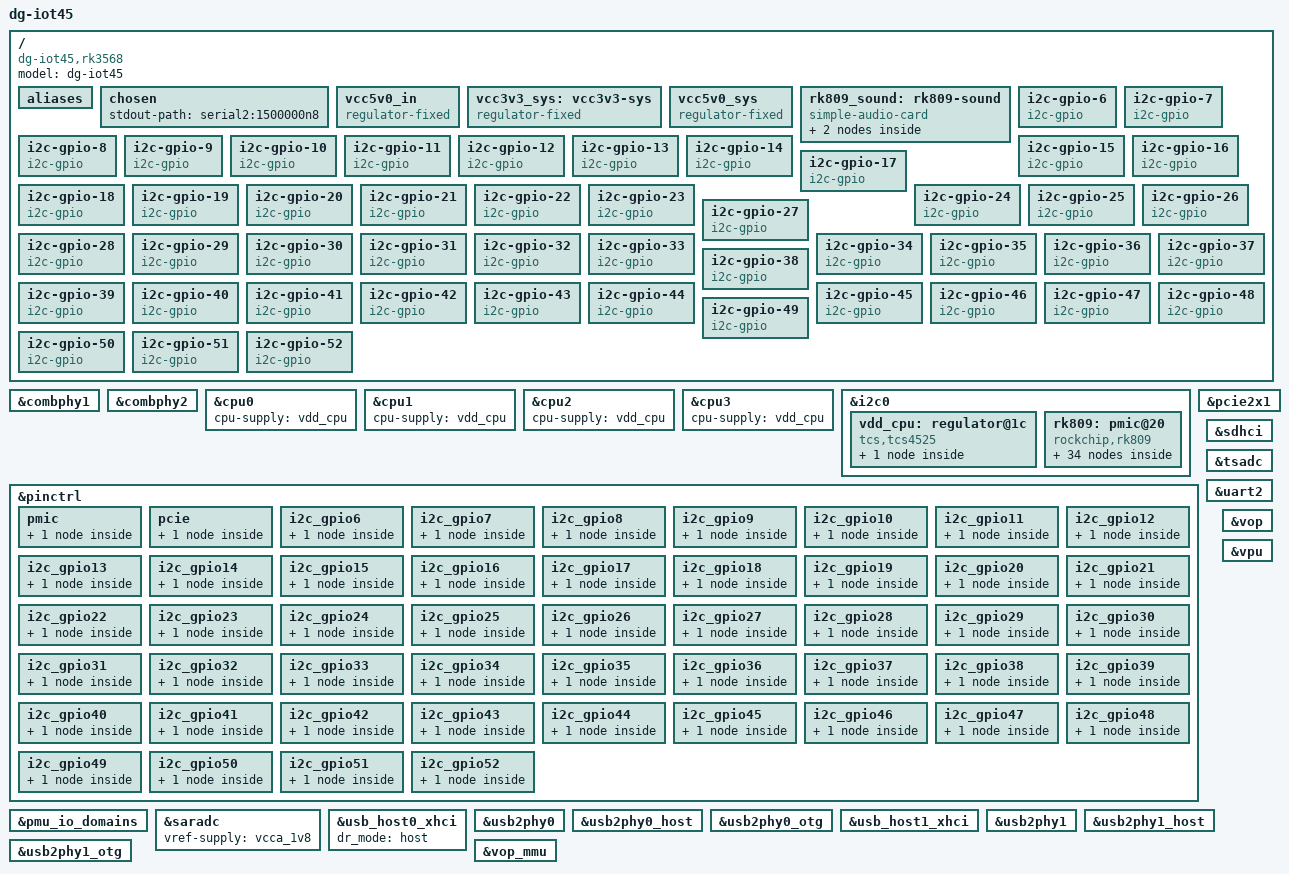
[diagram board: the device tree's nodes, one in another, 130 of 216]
// SPDX-License-Identifier: (GPL-2.0+ OR MIT)
/*
 * Copyright (c) 2020 Rockchip Electronics Co., Ltd.
 *
 */

/dts-v1/;

#include <dt-bindings/gpio/gpio.h>
#include <dt-bindings/input/input.h>
#include <dt-bindings/pinctrl/rockchip.h>
#include <dt-bindings/soc/rockchip,vop2.h>
#include "rk3568.dtsi"

/ {
	model = "dg-iot45";
	compatible = "dg-iot45,rk3568", "rockchip,rk3568";

	aliases {
		ethernet0 = &gmac1;
		mmc0 = &sdmmc0;
		mmc1 = &sdhci;
		mmc2 = &sdmmc1;
	};

	chosen: chosen {
		stdout-path = "serial2:1500000n8";
	};

	vcc5v0_in: vcc5v0_in {
		compatible = "regulator-fixed";
		regulator-name = "vcc5v0_in";
		regulator-always-on;
		regulator-boot-on;
		regulator-min-microvolt = <5000000>;
		regulator-max-microvolt = <5000000>;
	};

	vcc3v3_sys: vcc3v3-sys {
		compatible = "regulator-fixed";
		regulator-name = "vcc3v3_sys";
		regulator-always-on;
		regulator-boot-on;
		regulator-min-microvolt = <3300000>;
		regulator-max-microvolt = <3300000>;
		vin-supply = <&vcc5v0_sys>;
	};

	vcc5v0_sys: vcc5v0_sys {
		compatible = "regulator-fixed";
		regulator-name = "vcc5v0_sys";
		regulator-always-on;
		regulator-boot-on;
		regulator-min-microvolt = <5000000>;
		regulator-max-microvolt = <5000000>;
		vin-supply = <&vcc5v0_in>;
	};

	rk809_sound: rk809-sound {
		status = "okay";
		compatible = "simple-audio-card";
		simple-audio-card,format = "i2s";
		simple-audio-card,name = "rockchip,rk809-codec";
		simple-audio-card,mclk-fs = <256>;

		simple-audio-card,cpu {
			sound-dai = <&i2s1_8ch>;
		};
		simple-audio-card,codec {
			sound-dai = <&rk809_codec>;
		};
	};

	i2c-gpio-6 {
               compatible = "i2c-gpio";
               gpios = <&gpio0 RK_PC1 GPIO_ACTIVE_HIGH>, /* sda */
                               <&gpio0 RK_PC0 GPIO_ACTIVE_HIGH>; /* scl */
               i2c-gpio,sda-open-drain;
               i2c-gpio,scl-open-drain;
               i2c-gpio,delay-us = <2>;        /* ~100 kHz */
               #address-cells = <1>;
               #size-cells = <0>;
               pinctrl-names = "default";
               pinctrl-0 = <&pinctrl_i2c_gpio6>;
               status = "okay";
       };

       i2c-gpio-7 {
               compatible = "i2c-gpio";
               gpios = <&gpio0 RK_PC3 GPIO_ACTIVE_HIGH>, /* sda */
                               <&gpio0 RK_PC2 GPIO_ACTIVE_HIGH>; /* scl */
               i2c-gpio,sda-open-drain;
               i2c-gpio,scl-open-drain;
               i2c-gpio,delay-us = <2>;        /* ~100 kHz */
               #address-cells = <1>;
               #size-cells = <0>;
               pinctrl-names = "default";
               pinctrl-0 = <&pinctrl_i2c_gpio7>;
               status = "okay";
       };

       i2c-gpio-8 {
               compatible = "i2c-gpio";
               gpios = <&gpio0 RK_PC5 GPIO_ACTIVE_HIGH>, /* sda */
                               <&gpio0 RK_PC4 GPIO_ACTIVE_HIGH>; /* scl */
               i2c-gpio,sda-open-drain;
               i2c-gpio,scl-open-drain;
               i2c-gpio,delay-us = <2>;        /* ~100 kHz */
               #address-cells = <1>;
               #size-cells = <0>;
               pinctrl-names = "default";
               pinctrl-0 = <&pinctrl_i2c_gpio8>;
               status = "okay";
       };

       i2c-gpio-9 {
               compatible = "i2c-gpio";
               gpios = <&gpio0 RK_PC7 GPIO_ACTIVE_HIGH>, /* sda */
                               <&gpio0 RK_PC6 GPIO_ACTIVE_HIGH>; /* scl */
               i2c-gpio,sda-open-drain;
               i2c-gpio,scl-open-drain;
               i2c-gpio,delay-us = <2>;        /* ~100 kHz */
               #address-cells = <1>;
               #size-cells = <0>;
               pinctrl-names = "default";
               pinctrl-0 = <&pinctrl_i2c_gpio9>;
               status = "okay";
       };

       i2c-gpio-10 {
               compatible = "i2c-gpio";
               gpios = <&gpio4 RK_PC3 GPIO_ACTIVE_HIGH>, /* sda */
                               <&gpio4 RK_PC2 GPIO_ACTIVE_HIGH>; /* scl */
               i2c-gpio,sda-open-drain;
               i2c-gpio,scl-open-drain;
               i2c-gpio,delay-us = <2>;        /* ~100 kHz */
               #address-cells = <1>;
               #size-cells = <0>;
               pinctrl-names = "default";
               pinctrl-0 = <&pinctrl_i2c_gpio10>;
               status = "okay";
       };

       i2c-gpio-11 {
               compatible = "i2c-gpio";
               gpios = <&gpio4 RK_PC5 GPIO_ACTIVE_HIGH>, /* sda */
                               <&gpio4 RK_PC4 GPIO_ACTIVE_HIGH>; /* scl */
               i2c-gpio,sda-open-drain;
               i2c-gpio,scl-open-drain;
               i2c-gpio,delay-us = <2>;        /* ~100 kHz */
               #address-cells = <1>;
               #size-cells = <0>;
               pinctrl-names = "default";
               pinctrl-0 = <&pinctrl_i2c_gpio11>;
               status = "okay";
       };

       i2c-gpio-12 {
               compatible = "i2c-gpio";
               gpios = <&gpio0 RK_PB4 GPIO_ACTIVE_HIGH>, /* sda */
                               <&gpio0 RK_PB3 GPIO_ACTIVE_HIGH>; /* scl */
               i2c-gpio,sda-open-drain;
               i2c-gpio,scl-open-drain;
               i2c-gpio,delay-us = <2>;        /* ~100 kHz */
               #address-cells = <1>;
               #size-cells = <0>;
               pinctrl-names = "default";
               pinctrl-0 = <&pinctrl_i2c_gpio12>;
               status = "okay";
       };

       i2c-gpio-13 {
               compatible = "i2c-gpio";
               gpios = <&gpio0 RK_PB6 GPIO_ACTIVE_HIGH>, /* sda */
                               <&gpio0 RK_PB5 GPIO_ACTIVE_HIGH>; /* scl */
               i2c-gpio,sda-open-drain;
               i2c-gpio,scl-open-drain;
               i2c-gpio,delay-us = <2>;        /* ~100 kHz */
               #address-cells = <1>;
               #size-cells = <0>;
               pinctrl-names = "default";
               pinctrl-0 = <&pinctrl_i2c_gpio13>;
               status = "okay";
       };

       i2c-gpio-14 {
               compatible = "i2c-gpio";
               gpios = <&gpio1 RK_PA1 GPIO_ACTIVE_HIGH>, /* sda */
                               <&gpio1 RK_PA0 GPIO_ACTIVE_HIGH>; /* scl */
               i2c-gpio,sda-open-drain;
               i2c-gpio,scl-open-drain;
               i2c-gpio,delay-us = <2>;        /* ~100 kHz */
               #address-cells = <1>;
               #size-cells = <0>;
               pinctrl-names = "default";
               pinctrl-0 = <&pinctrl_i2c_gpio14>;
               status = "okay";
       };

       i2c-gpio-15 {
               compatible = "i2c-gpio";
               gpios = <&gpio2 RK_PA4 GPIO_ACTIVE_HIGH>, /* sda */
                               <&gpio2 RK_PA3 GPIO_ACTIVE_HIGH>; /* scl */
               i2c-gpio,sda-open-drain;
               i2c-gpio,scl-open-drain;
               i2c-gpio,delay-us = <2>;        /* ~100 kHz */
               #address-cells = <1>;
               #size-cells = <0>;
               pinctrl-names = "default";
               pinctrl-0 = <&pinctrl_i2c_gpio15>;
               status = "okay";
       };

       i2c-gpio-16 {
               compatible = "i2c-gpio";
               gpios = <&gpio2 RK_PA6 GPIO_ACTIVE_HIGH>, /* sda */
                               <&gpio2 RK_PA5 GPIO_ACTIVE_HIGH>; /* scl */
               i2c-gpio,sda-open-drain;
               i2c-gpio,scl-open-drain;
               i2c-gpio,delay-us = <2>;        /* ~100 kHz */
               #address-cells = <1>;
               #size-cells = <0>;
               pinctrl-names = "default";
               pinctrl-0 = <&pinctrl_i2c_gpio16>;
               status = "okay";
       };

       i2c-gpio-17 {
               compatible = "i2c-gpio";
               gpios = <&gpio2 RK_PB0 GPIO_ACTIVE_HIGH>, /* sda */
                               <&gpio2 RK_PA7 GPIO_ACTIVE_HIGH>; /* scl */
               i2c-gpio,sda-open-drain;
               i2c-gpio,scl-open-drain;
               i2c-gpio,delay-us = <2>;        /* ~100 kHz */
               #address-cells = <1>;
               #size-cells = <0>;
               pinctrl-names = "default";
               pinctrl-0 = <&pinctrl_i2c_gpio17>;
               status = "okay";
       };

       i2c-gpio-18 {
               compatible = "i2c-gpio";
               gpios = <&gpio2 RK_PB2 GPIO_ACTIVE_HIGH>, /* sda */
                               <&gpio2 RK_PB1 GPIO_ACTIVE_HIGH>; /* scl */
               i2c-gpio,sda-open-drain;
               i2c-gpio,scl-open-drain;
               i2c-gpio,delay-us = <2>;        /* ~100 kHz */
               #address-cells = <1>;
               #size-cells = <0>;
               pinctrl-names = "default";
               pinctrl-0 = <&pinctrl_i2c_gpio18>;
               status = "okay";
       };

       i2c-gpio-19 {
               compatible = "i2c-gpio";
               gpios = <&gpio2 RK_PB4 GPIO_ACTIVE_HIGH>, /* sda */
                               <&gpio2 RK_PB3 GPIO_ACTIVE_HIGH>; /* scl */
               i2c-gpio,sda-open-drain;
               i2c-gpio,scl-open-drain;
               i2c-gpio,delay-us = <2>;        /* ~100 kHz */
               #address-cells = <1>;
               #size-cells = <0>;
               pinctrl-names = "default";
               pinctrl-0 = <&pinctrl_i2c_gpio19>;
               status = "okay";
       };

       i2c-gpio-20 {
               compatible = "i2c-gpio";
               gpios = <&gpio2 RK_PB6 GPIO_ACTIVE_HIGH>, /* sda */
                               <&gpio2 RK_PB5 GPIO_ACTIVE_HIGH>; /* scl */
               i2c-gpio,sda-open-drain;
               i2c-gpio,scl-open-drain;
               i2c-gpio,delay-us = <2>;        /* ~100 kHz */
               #address-cells = <1>;
               #size-cells = <0>;
               pinctrl-names = "default";
               pinctrl-0 = <&pinctrl_i2c_gpio20>;
               status = "okay";
       };

       i2c-gpio-21 {
               compatible = "i2c-gpio";
               gpios = <&gpio2 RK_PC0 GPIO_ACTIVE_HIGH>, /* sda */
                               <&gpio2 RK_PB7 GPIO_ACTIVE_HIGH>; /* scl */
               i2c-gpio,sda-open-drain;
               i2c-gpio,scl-open-drain;
               i2c-gpio,delay-us = <2>;        /* ~100 kHz */
               #address-cells = <1>;
               #size-cells = <0>;
               pinctrl-names = "default";
               pinctrl-0 = <&pinctrl_i2c_gpio21>;
               status = "okay";
       };

       i2c-gpio-22 {
               compatible = "i2c-gpio";
               gpios = <&gpio2 RK_PC2 GPIO_ACTIVE_HIGH>, /* sda */
                               <&gpio2 RK_PC1 GPIO_ACTIVE_HIGH>; /* scl */
               i2c-gpio,sda-open-drain;
               i2c-gpio,scl-open-drain;
               i2c-gpio,delay-us = <2>;        /* ~100 kHz */
               #address-cells = <1>;
               #size-cells = <0>;
               pinctrl-names = "default";
               pinctrl-0 = <&pinctrl_i2c_gpio22>;
               status = "okay";
       };

       i2c-gpio-23 {
               compatible = "i2c-gpio";
               gpios = <&gpio2 RK_PC4 GPIO_ACTIVE_HIGH>, /* sda */
                               <&gpio2 RK_PC3 GPIO_ACTIVE_HIGH>; /* scl */
               i2c-gpio,sda-open-drain;
               i2c-gpio,scl-open-drain;
               i2c-gpio,delay-us = <2>;        /* ~100 kHz */
               #address-cells = <1>;
               #size-cells = <0>;
               pinctrl-names = "default";
               pinctrl-0 = <&pinctrl_i2c_gpio23>;
               status = "okay";
       };

       i2c-gpio-24 {
               compatible = "i2c-gpio";
               gpios = <&gpio2 RK_PC6 GPIO_ACTIVE_HIGH>, /* sda */
                               <&gpio2 RK_PC5 GPIO_ACTIVE_HIGH>; /* scl */
               i2c-gpio,sda-open-drain;
               i2c-gpio,scl-open-drain;
               i2c-gpio,delay-us = <2>;        /* ~100 kHz */
               #address-cells = <1>;
               #size-cells = <0>;
               pinctrl-names = "default";
               pinctrl-0 = <&pinctrl_i2c_gpio24>;
               status = "okay";
       };

       i2c-gpio-25 {
               compatible = "i2c-gpio";
               gpios = <&gpio0 RK_PA4 GPIO_ACTIVE_HIGH>, /* sda */
                               <&gpio0 RK_PA5 GPIO_ACTIVE_HIGH>; /* scl */
               i2c-gpio,sda-open-drain;
               i2c-gpio,scl-open-drain;
               i2c-gpio,delay-us = <2>;        /* ~100 kHz */
               #address-cells = <1>;
               #size-cells = <0>;
               pinctrl-names = "default";
               pinctrl-0 = <&pinctrl_i2c_gpio25>;
               status = "okay";
       };

       i2c-gpio-26 {
               compatible = "i2c-gpio";
               gpios = <&gpio2 RK_PA1 GPIO_ACTIVE_HIGH>, /* sda */
                               <&gpio2 RK_PA2 GPIO_ACTIVE_HIGH>; /* scl */
               i2c-gpio,sda-open-drain;
               i2c-gpio,scl-open-drain;
               i2c-gpio,delay-us = <2>;        /* ~100 kHz */
               #address-cells = <1>;
               #size-cells = <0>;
               pinctrl-names = "default";
               pinctrl-0 = <&pinctrl_i2c_gpio26>;
               status = "okay";
       };

       i2c-gpio-27 {
               compatible = "i2c-gpio";
               gpios = <&gpio1 RK_PD7 GPIO_ACTIVE_HIGH>, /* sda */
                               <&gpio2 RK_PA0 GPIO_ACTIVE_HIGH>; /* scl */
               i2c-gpio,sda-open-drain;
               i2c-gpio,scl-open-drain;
               i2c-gpio,delay-us = <2>;        /* ~100 kHz */
               #address-cells = <1>;
               #size-cells = <0>;
               pinctrl-names = "default";
               pinctrl-0 = <&pinctrl_i2c_gpio27>;
               status = "okay";
       };

       i2c-gpio-28 {
               compatible = "i2c-gpio";
               gpios = <&gpio1 RK_PD5 GPIO_ACTIVE_HIGH>, /* sda */
                               <&gpio1 RK_PD6 GPIO_ACTIVE_HIGH>; /* scl */
               i2c-gpio,sda-open-drain;
               i2c-gpio,scl-open-drain;
               i2c-gpio,delay-us = <2>;        /* ~100 kHz */
               #address-cells = <1>;
               #size-cells = <0>;
               pinctrl-names = "default";
               pinctrl-0 = <&pinctrl_i2c_gpio28>;
               status = "okay";
       };

       i2c-gpio-29 {
               compatible = "i2c-gpio";
               gpios = <&gpio4 RK_PC0 GPIO_ACTIVE_HIGH>, /* sda */
                               <&gpio4 RK_PC1 GPIO_ACTIVE_HIGH>; /* scl */
               i2c-gpio,sda-open-drain;
               i2c-gpio,scl-open-drain;
               i2c-gpio,delay-us = <2>;        /* ~100 kHz */
               #address-cells = <1>;
               #size-cells = <0>;
               pinctrl-names = "default";
               pinctrl-0 = <&pinctrl_i2c_gpio29>;
               status = "okay";
       };

       i2c-gpio-30 {
               compatible = "i2c-gpio";
               gpios = <&gpio4 RK_PB6 GPIO_ACTIVE_HIGH>, /* sda */
                               <&gpio4 RK_PB7 GPIO_ACTIVE_HIGH>; /* scl */
               i2c-gpio,sda-open-drain;
               i2c-gpio,scl-open-drain;
               i2c-gpio,delay-us = <2>;        /* ~100 kHz */
               #address-cells = <1>;
               #size-cells = <0>;
               pinctrl-names = "default";
               pinctrl-0 = <&pinctrl_i2c_gpio30>;
               status = "okay";
       };

       i2c-gpio-31 {
               compatible = "i2c-gpio";
               gpios = <&gpio4 RK_PB4 GPIO_ACTIVE_HIGH>, /* sda */
                               <&gpio4 RK_PB5 GPIO_ACTIVE_HIGH>; /* scl */
               i2c-gpio,sda-open-drain;
               i2c-gpio,scl-open-drain;
               i2c-gpio,delay-us = <2>;        /* ~100 kHz */
               #address-cells = <1>;
               #size-cells = <0>;
               pinctrl-names = "default";
               pinctrl-0 = <&pinctrl_i2c_gpio31>;
               status = "okay";
       };

       i2c-gpio-32 {
               compatible = "i2c-gpio";
               gpios = <&gpio4 RK_PB2 GPIO_ACTIVE_HIGH>, /* sda */
                               <&gpio4 RK_PB3 GPIO_ACTIVE_HIGH>; /* scl */
               i2c-gpio,sda-open-drain;
               i2c-gpio,scl-open-drain;
               i2c-gpio,delay-us = <2>;        /* ~100 kHz */
               #address-cells = <1>;
               #size-cells = <0>;
               pinctrl-names = "default";
               pinctrl-0 = <&pinctrl_i2c_gpio32>;
               status = "okay";
       };

       i2c-gpio-33 {
               compatible = "i2c-gpio";
               gpios = <&gpio4 RK_PB0 GPIO_ACTIVE_HIGH>, /* sda */
                               <&gpio4 RK_PB1 GPIO_ACTIVE_HIGH>; /* scl */
               i2c-gpio,sda-open-drain;
               i2c-gpio,scl-open-drain;
               i2c-gpio,delay-us = <2>;        /* ~100 kHz */
               #address-cells = <1>;
               #size-cells = <0>;
               pinctrl-names = "default";
               pinctrl-0 = <&pinctrl_i2c_gpio33>;
               status = "okay";
       };

       i2c-gpio-34 {
               compatible = "i2c-gpio";
               gpios = <&gpio4 RK_PA6 GPIO_ACTIVE_HIGH>, /* sda */
                               <&gpio4 RK_PA7 GPIO_ACTIVE_HIGH>; /* scl */
               i2c-gpio,sda-open-drain;
               i2c-gpio,scl-open-drain;
               i2c-gpio,delay-us = <2>;        /* ~100 kHz */
               #address-cells = <1>;
               #size-cells = <0>;
               pinctrl-names = "default";
               pinctrl-0 = <&pinctrl_i2c_gpio34>;
               status = "okay";
       };

       i2c-gpio-35 {
               compatible = "i2c-gpio";
               gpios = <&gpio4 RK_PA4 GPIO_ACTIVE_HIGH>, /* sda */
                               <&gpio4 RK_PA5 GPIO_ACTIVE_HIGH>; /* scl */
               i2c-gpio,sda-open-drain;
               i2c-gpio,scl-open-drain;
               i2c-gpio,delay-us = <2>;        /* ~100 kHz */
               #address-cells = <1>;
               #size-cells = <0>;
               pinctrl-names = "default";
               pinctrl-0 = <&pinctrl_i2c_gpio35>;
               status = "okay";
       };

       i2c-gpio-36 {
               compatible = "i2c-gpio";
               gpios = <&gpio4 RK_PA2 GPIO_ACTIVE_HIGH>, /* sda */
                               <&gpio4 RK_PA3 GPIO_ACTIVE_HIGH>; /* scl */
               i2c-gpio,sda-open-drain;
               i2c-gpio,scl-open-drain;
               i2c-gpio,delay-us = <2>;        /* ~100 kHz */
               #address-cells = <1>;
               #size-cells = <0>;
               pinctrl-names = "default";
               pinctrl-0 = <&pinctrl_i2c_gpio36>;
               status = "okay";
       };

       i2c-gpio-37 {
               compatible = "i2c-gpio";
               gpios = <&gpio4 RK_PA0 GPIO_ACTIVE_HIGH>, /* sda */
                               <&gpio4 RK_PA1 GPIO_ACTIVE_HIGH>; /* scl */
               i2c-gpio,sda-open-drain;
               i2c-gpio,scl-open-drain;
               i2c-gpio,delay-us = <2>;        /* ~100 kHz */
               #address-cells = <1>;
               #size-cells = <0>;
               pinctrl-names = "default";
               pinctrl-0 = <&pinctrl_i2c_gpio37>;
               status = "okay";
       };

       i2c-gpio-38 {
               compatible = "i2c-gpio";
               gpios = <&gpio3 RK_PD6 GPIO_ACTIVE_HIGH>, /* sda */
                               <&gpio3 RK_PD7 GPIO_ACTIVE_HIGH>; /* scl */
               i2c-gpio,sda-open-drain;
               i2c-gpio,scl-open-drain;
               i2c-gpio,delay-us = <2>;        /* ~100 kHz */
               #address-cells = <1>;
               #size-cells = <0>;
               pinctrl-names = "default";
               pinctrl-0 = <&pinctrl_i2c_gpio38>;
               status = "okay";
       };

       i2c-gpio-39 {
               compatible = "i2c-gpio";
               gpios = <&gpio3 RK_PD4 GPIO_ACTIVE_HIGH>, /* sda */
                               <&gpio3 RK_PD5 GPIO_ACTIVE_HIGH>; /* scl */
               i2c-gpio,sda-open-drain;
               i2c-gpio,scl-open-drain;
               i2c-gpio,delay-us = <2>;        /* ~100 kHz */
               #address-cells = <1>;
               #size-cells = <0>;
               pinctrl-names = "default";
               pinctrl-0 = <&pinctrl_i2c_gpio39>;
               status = "okay";
       };

       i2c-gpio-40 {
               compatible = "i2c-gpio";
               gpios = <&gpio3 RK_PD2 GPIO_ACTIVE_HIGH>, /* sda */
                               <&gpio3 RK_PD3 GPIO_ACTIVE_HIGH>; /* scl */
               i2c-gpio,sda-open-drain;
               i2c-gpio,scl-open-drain;
               i2c-gpio,delay-us = <2>;        /* ~100 kHz */
               #address-cells = <1>;
               #size-cells = <0>;
               pinctrl-names = "default";
               pinctrl-0 = <&pinctrl_i2c_gpio40>;
               status = "okay";
       };

       i2c-gpio-41 {
               compatible = "i2c-gpio";
               gpios = <&gpio3 RK_PD0 GPIO_ACTIVE_HIGH>, /* sda */
                               <&gpio3 RK_PD1 GPIO_ACTIVE_HIGH>; /* scl */
               i2c-gpio,sda-open-drain;
               i2c-gpio,scl-open-drain;
               i2c-gpio,delay-us = <2>;        /* ~100 kHz */
               #address-cells = <1>;
               #size-cells = <0>;
               pinctrl-names = "default";
               pinctrl-0 = <&pinctrl_i2c_gpio41>;
               status = "okay";
       };

       i2c-gpio-42 {
               compatible = "i2c-gpio";
               gpios = <&gpio3 RK_PC6 GPIO_ACTIVE_HIGH>, /* sda */
                               <&gpio3 RK_PC7 GPIO_ACTIVE_HIGH>; /* scl */
               i2c-gpio,sda-open-drain;
               i2c-gpio,scl-open-drain;
               i2c-gpio,delay-us = <2>;        /* ~100 kHz */
               #address-cells = <1>;
               #size-cells = <0>;
               pinctrl-names = "default";
               pinctrl-0 = <&pinctrl_i2c_gpio42>;
               status = "okay";
       };

       i2c-gpio-43 {
               compatible = "i2c-gpio";
               gpios = <&gpio3 RK_PC4 GPIO_ACTIVE_HIGH>, /* sda */
                               <&gpio3 RK_PC5 GPIO_ACTIVE_HIGH>; /* scl */
               i2c-gpio,sda-open-drain;
               i2c-gpio,scl-open-drain;
               i2c-gpio,delay-us = <2>;        /* ~100 kHz */
               #address-cells = <1>;
               #size-cells = <0>;
               pinctrl-names = "default";
               pinctrl-0 = <&pinctrl_i2c_gpio43>;
               status = "okay";
       };

       i2c-gpio-44 {
               compatible = "i2c-gpio";
               gpios = <&gpio3 RK_PC2 GPIO_ACTIVE_HIGH>, /* sda */
                               <&gpio3 RK_PC3 GPIO_ACTIVE_HIGH>; /* scl */
               i2c-gpio,sda-open-drain;
               i2c-gpio,scl-open-drain;
               i2c-gpio,delay-us = <2>;        /* ~100 kHz */
               #address-cells = <1>;
               #size-cells = <0>;
               pinctrl-names = "default";
               pinctrl-0 = <&pinctrl_i2c_gpio44>;
               status = "okay";
       };

       i2c-gpio-45 {
               compatible = "i2c-gpio";
               gpios = <&gpio3 RK_PC0 GPIO_ACTIVE_HIGH>, /* sda */
                               <&gpio3 RK_PC1 GPIO_ACTIVE_HIGH>; /* scl */
               i2c-gpio,sda-open-drain;
               i2c-gpio,scl-open-drain;
               i2c-gpio,delay-us = <2>;        /* ~100 kHz */
               #address-cells = <1>;
               #size-cells = <0>;
               pinctrl-names = "default";
               pinctrl-0 = <&pinctrl_i2c_gpio45>;
               status = "okay";
       };

       i2c-gpio-46 {
               compatible = "i2c-gpio";
               gpios = <&gpio3 RK_PB6 GPIO_ACTIVE_HIGH>, /* sda */
                               <&gpio3 RK_PB7 GPIO_ACTIVE_HIGH>; /* scl */
               i2c-gpio,sda-open-drain;
               i2c-gpio,scl-open-drain;
               i2c-gpio,delay-us = <2>;        /* ~100 kHz */
               #address-cells = <1>;
               #size-cells = <0>;
               pinctrl-names = "default";
               pinctrl-0 = <&pinctrl_i2c_gpio46>;
               status = "okay";
       };

       i2c-gpio-47 {
               compatible = "i2c-gpio";
               gpios = <&gpio3 RK_PB4 GPIO_ACTIVE_HIGH>, /* sda */
                               <&gpio3 RK_PB5 GPIO_ACTIVE_HIGH>; /* scl */
               i2c-gpio,sda-open-drain;
               i2c-gpio,scl-open-drain;
               i2c-gpio,delay-us = <2>;        /* ~100 kHz */
               #address-cells = <1>;
               #size-cells = <0>;
               pinctrl-names = "default";
               pinctrl-0 = <&pinctrl_i2c_gpio47>;
               status = "okay";
       };

       i2c-gpio-48 {
               compatible = "i2c-gpio";
               gpios = <&gpio3 RK_PB2 GPIO_ACTIVE_HIGH>, /* sda */
                               <&gpio3 RK_PB3 GPIO_ACTIVE_HIGH>; /* scl */
               i2c-gpio,sda-open-drain;
               i2c-gpio,scl-open-drain;
               i2c-gpio,delay-us = <2>;        /* ~100 kHz */
               #address-cells = <1>;
               #size-cells = <0>;
               pinctrl-names = "default";
               pinctrl-0 = <&pinctrl_i2c_gpio48>;
               status = "okay";
       };

       i2c-gpio-49 {
               compatible = "i2c-gpio";
               gpios = <&gpio3 RK_PB0 GPIO_ACTIVE_HIGH>, /* sda */
                               <&gpio3 RK_PB1 GPIO_ACTIVE_HIGH>; /* scl */
               i2c-gpio,sda-open-drain;
               i2c-gpio,scl-open-drain;
               i2c-gpio,delay-us = <2>;        /* ~100 kHz */
               #address-cells = <1>;
               #size-cells = <0>;
               pinctrl-names = "default";
               pinctrl-0 = <&pinctrl_i2c_gpio49>;
               status = "okay";
       };

       i2c-gpio-50 {
               compatible = "i2c-gpio";
               gpios = <&gpio3 RK_PA6 GPIO_ACTIVE_HIGH>, /* sda */
                               <&gpio3 RK_PA7 GPIO_ACTIVE_HIGH>; /* scl */
               i2c-gpio,sda-open-drain;
               i2c-gpio,scl-open-drain;
               i2c-gpio,delay-us = <2>;        /* ~100 kHz */
               #address-cells = <1>;
               #size-cells = <0>;
               pinctrl-names = "default";
               pinctrl-0 = <&pinctrl_i2c_gpio50>;
               status = "okay";
       };

       i2c-gpio-51 {
               compatible = "i2c-gpio";
               gpios = <&gpio3 RK_PA4 GPIO_ACTIVE_HIGH>, /* sda */
                               <&gpio3 RK_PA5 GPIO_ACTIVE_HIGH>; /* scl */
               i2c-gpio,sda-open-drain;
               i2c-gpio,scl-open-drain;
               i2c-gpio,delay-us = <2>;        /* ~100 kHz */
               #address-cells = <1>;
               #size-cells = <0>;
               pinctrl-names = "default";
               pinctrl-0 = <&pinctrl_i2c_gpio51>;
               status = "okay";
       };

       i2c-gpio-52 {
               compatible = "i2c-gpio";
               gpios = <&gpio3 RK_PA2 GPIO_ACTIVE_HIGH>, /* sda */
                               <&gpio3 RK_PA3 GPIO_ACTIVE_HIGH>; /* scl */
               i2c-gpio,sda-open-drain;
               i2c-gpio,scl-open-drain;
               i2c-gpio,delay-us = <2>;        /* ~100 kHz */
               #address-cells = <1>;
               #size-cells = <0>;
               pinctrl-names = "default";
               pinctrl-0 = <&pinctrl_i2c_gpio52>;
               status = "okay";
       };

};

&combphy1 {
	status = "okay";
};

&combphy2 {
	status = "okay";
};

&cpu0 {
	cpu-supply = <&vdd_cpu>;
};

&cpu1 {
	cpu-supply = <&vdd_cpu>;
};

&cpu2 {
	cpu-supply = <&vdd_cpu>;
};

&cpu3 {
	cpu-supply = <&vdd_cpu>;
};



&i2c0 {
	status = "okay";

	vdd_cpu: regulator@1c {
		compatible = "tcs,tcs4525";
		reg = <0x1c>;
		fcs,suspend-voltage-selector = <1>;
		regulator-name = "vdd_cpu";
		regulator-min-microvolt = <800000>;
		regulator-max-microvolt = <1150000>;
		regulator-ramp-delay = <2300>;
		regulator-always-on;
		regulator-boot-on;
		vin-supply = <&vcc5v0_sys>;

		regulator-state-mem {
			regulator-off-in-suspend;
		};
	};

	rk809: pmic@20 {
		compatible = "rockchip,rk809";
		reg = <0x20>;
		interrupt-parent = <&gpio0>;
		interrupts = <RK_PA3 IRQ_TYPE_LEVEL_LOW>;
		#clock-cells = <1>;
		#sound-dai-cells = <0>;
		clock-output-names = "rk808-clkout1", "rk808-clkout2";
		pinctrl-names = "default";
		pinctrl-0 = <&pmic_int_l>;
		rockchip,system-power-controller;
		wakeup-source;

		vcc1-supply = <&vcc3v3_sys>;
		vcc2-supply = <&vcc3v3_sys>;
		vcc3-supply = <&vcc3v3_sys>;
		vcc4-supply = <&vcc3v3_sys>;
		vcc5-supply = <&vcc3v3_sys>;
		vcc6-supply = <&vcc3v3_sys>;
		vcc7-supply = <&vcc3v3_sys>;
		vcc8-supply = <&vcc3v3_sys>;
		vcc9-supply = <&vcc3v3_sys>;

		regulators {
			vdd_logic: DCDC_REG1 {
				regulator-name = "vdd_logic";
				regulator-always-on;
				regulator-boot-on;
				regulator-min-microvolt = <500000>;
				regulator-max-microvolt = <1350000>;
				regulator-init-microvolt = <900000>;
				regulator-ramp-delay = <6001>;
				regulator-initial-mode = <0x2>;
				regulator-state-mem {
					regulator-off-in-suspend;
				};
			};

			vdd_gpu: DCDC_REG2 {
				regulator-name = "vdd_gpu";
				regulator-always-on;
				regulator-boot-on;
				regulator-min-microvolt = <500000>;
				regulator-max-microvolt = <1350000>;
				regulator-init-microvolt = <900000>;
				regulator-ramp-delay = <6001>;
				regulator-initial-mode = <0x2>;
					regulator-state-mem {
					regulator-off-in-suspend;
				};
			};

			vcc_ddr: DCDC_REG3 {
				regulator-always-on;
				regulator-boot-on;
				regulator-initial-mode = <0x2>;
				regulator-name = "vcc_ddr";
				regulator-state-mem {
					regulator-on-in-suspend;
				};
			};

			vdd_npu: DCDC_REG4 {
				regulator-always-on;
				regulator-boot-on;
				regulator-min-microvolt = <500000>;
				regulator-max-microvolt = <1350000>;
				regulator-init-microvolt = <900000>;
				regulator-initial-mode = <0x2>;
				regulator-name = "vdd_npu";
				regulator-state-mem {
					regulator-off-in-suspend;
				};
			};

			vdda0v9_image: LDO_REG1 {
				regulator-always-on;
				regulator-boot-on;
				regulator-min-microvolt = <900000>;
				regulator-max-microvolt = <900000>;
				regulator-name = "vdda0v9_image";
				regulator-state-mem {
					regulator-off-in-suspend;
				};
			};

			vdda_0v9: LDO_REG2 {
				regulator-always-on;
				regulator-boot-on;
				regulator-min-microvolt = <900000>;
				regulator-max-microvolt = <900000>;
				regulator-name = "vdda_0v9";
				regulator-state-mem {
					regulator-off-in-suspend;
				};
			};

			vdda0v9_pmu: LDO_REG3 {
				regulator-always-on;
				regulator-boot-on;
				regulator-min-microvolt = <900000>;
				regulator-max-microvolt = <900000>;
				regulator-name = "vdda0v9_pmu";
				regulator-state-mem {
					regulator-on-in-suspend;
					regulator-suspend-microvolt = <900000>;
				};
			};

			vccio_acodec: LDO_REG4 {
				regulator-always-on;
				regulator-boot-on;
				regulator-min-microvolt = <3300000>;
				regulator-max-microvolt = <3300000>;
				regulator-name = "vccio_acodec";
				regulator-state-mem {
					regulator-off-in-suspend;
				};
			};

			vccio_sd: LDO_REG5 {
				regulator-name = "vccio_sd";
				regulator-always-on;
				regulator-boot-on;
				regulator-min-microvolt = <1800000>;
				regulator-max-microvolt = <3300000>;

				regulator-state-mem {
					regulator-off-in-suspend;
				};
			};

			vcc3v3_pmu: LDO_REG6 {
				regulator-name = "vcc3v3_pmu";
				regulator-always-on;
				regulator-boot-on;
				regulator-min-microvolt = <3300000>;
				regulator-max-microvolt = <3300000>;

				regulator-state-mem {
					regulator-on-in-suspend;
					regulator-suspend-microvolt = <3300000>;
				};
			};

			vcca_1v8: LDO_REG7 {
				regulator-name = "vcca_1v8";
				regulator-always-on;
				regulator-boot-on;
				regulator-min-microvolt = <1800000>;
				regulator-max-microvolt = <1800000>;

				regulator-state-mem {
					regulator-off-in-suspend;
				};
			};

			vcca1v8_pmu: LDO_REG8 {
				regulator-name = "vcca1v8_pmu";
				regulator-always-on;
				regulator-boot-on;
				regulator-min-microvolt = <1800000>;
				regulator-max-microvolt = <1800000>;

				regulator-state-mem {
					regulator-on-in-suspend;
					regulator-suspend-microvolt = <1800000>;
				};
			};

			vcca1v8_image: LDO_REG9 {
				regulator-name = "vcca1v8_image";
				regulator-min-microvolt = <1800000>;
				regulator-max-microvolt = <1800000>;

				regulator-state-mem {
					regulator-off-in-suspend;
				};
			};

			vcc_1v8: DCDC_REG5 {
				regulator-always-on;
				regulator-boot-on;
				regulator-min-microvolt = <1800000>;
				regulator-max-microvolt = <1800000>;
				regulator-name = "vcc_1v8";
				regulator-state-mem {
					regulator-off-in-suspend;
				};
			};

			vcc_3v3: SWITCH_REG1 {
				regulator-name = "vcc_3v3";
				regulator-always-on;
				regulator-boot-on;

				regulator-state-mem {
					regulator-off-in-suspend;
				};
			};

			vcc3v3_sd: SWITCH_REG2 {
				regulator-name = "vcc3v3_sd";
				regulator-always-on;
				regulator-boot-on;

				regulator-state-mem {
					regulator-off-in-suspend;
				};
			};
		};

		rk809_codec: codec {
			mic-in-differential;
		};
	};
};


&pcie2x1 {
	pinctrl-names = "default";
	pinctrl-0 = <&pcie_reset_h>;
	reset-gpios = <&gpio3 RK_PA1 GPIO_ACTIVE_HIGH>;
	vpcie3v3-supply = <&vcc3v3_sys>;
	status = "okay";
};

&pinctrl {

	pmic {
		pmic_int_l: pmic-int-l {
			rockchip,pins = <0 RK_PA3 RK_FUNC_GPIO &pcfg_pull_up>;
		};
	};

	pcie {
		pcie_reset_h: pcie-reset-h {
			rockchip,pins = <3 RK_PA1 RK_FUNC_GPIO &pcfg_pull_none>;
		};
	};

	i2c_gpio6 {
               pinctrl_i2c_gpio6: i2c_gpio6-0 {
                       rockchip,pins =
                               <0 RK_PC1 RK_FUNC_GPIO &pcfg_pull_up>,
                               <0 RK_PC0 RK_FUNC_GPIO &pcfg_pull_up>;
               };
       };

       i2c_gpio7 {
               pinctrl_i2c_gpio7: i2c_gpio7-0 {
                       rockchip,pins =
                               <0 RK_PC3 RK_FUNC_GPIO &pcfg_pull_up>,
                               <0 RK_PC2 RK_FUNC_GPIO &pcfg_pull_up>;
               };
       };

       i2c_gpio8 {
               pinctrl_i2c_gpio8: i2c_gpio8-0 {
                       rockchip,pins =
                               <0 RK_PC5 RK_FUNC_GPIO &pcfg_pull_up>,
                               <0 RK_PC4 RK_FUNC_GPIO &pcfg_pull_up>;
               };
       };

       i2c_gpio9 {
               pinctrl_i2c_gpio9: i2c_gpio9-0 {
                       rockchip,pins =
                               <0 RK_PC7 RK_FUNC_GPIO &pcfg_pull_up>,
                               <0 RK_PC6 RK_FUNC_GPIO &pcfg_pull_up>;
               };
       };

       i2c_gpio10 {
               pinctrl_i2c_gpio10: i2c_gpio10-0 {
                       rockchip,pins =
                               <4 RK_PC3 RK_FUNC_GPIO &pcfg_pull_up>,
                               <4 RK_PC2 RK_FUNC_GPIO &pcfg_pull_up>;
               };
       };

       i2c_gpio11 {
               pinctrl_i2c_gpio11: i2c_gpio11-0 {
                       rockchip,pins =
                               <4 RK_PC5 RK_FUNC_GPIO &pcfg_pull_up>,
                               <4 RK_PC4 RK_FUNC_GPIO &pcfg_pull_up>;
               };
       };

       i2c_gpio12 {
               pinctrl_i2c_gpio12: i2c_gpio12-0 {
                       rockchip,pins =
                               <0 RK_PB4 RK_FUNC_GPIO &pcfg_pull_up>,
                               <0 RK_PB3 RK_FUNC_GPIO &pcfg_pull_up>;
               };
       };

       i2c_gpio13 {
               pinctrl_i2c_gpio13: i2c_gpio13-0 {
                       rockchip,pins =
                               <0 RK_PB6 RK_FUNC_GPIO &pcfg_pull_up>,
                               <0 RK_PB5 RK_FUNC_GPIO &pcfg_pull_up>;
               };
       };

       i2c_gpio14 {
               pinctrl_i2c_gpio14: i2c_gpio14-0 {
                       rockchip,pins =
                               <1 RK_PA1 RK_FUNC_GPIO &pcfg_pull_up>,
                               <1 RK_PA0 RK_FUNC_GPIO &pcfg_pull_up>;
               };
       };

       i2c_gpio15 {
               pinctrl_i2c_gpio15: i2c_gpio15-0 {
                       rockchip,pins =
                               <2 RK_PA4 RK_FUNC_GPIO &pcfg_pull_up>,
                               <2 RK_PA3 RK_FUNC_GPIO &pcfg_pull_up>;
               };
       };

       i2c_gpio16 {
               pinctrl_i2c_gpio16: i2c_gpio16-0 {
                       rockchip,pins =
                               <2 RK_PA6 RK_FUNC_GPIO &pcfg_pull_up>,
                               <2 RK_PA5 RK_FUNC_GPIO &pcfg_pull_up>;
               };
       };

       i2c_gpio17 {
               pinctrl_i2c_gpio17: i2c_gpio17-0 {
                       rockchip,pins =
                               <2 RK_PB0 RK_FUNC_GPIO &pcfg_pull_up>,
                               <2 RK_PA7 RK_FUNC_GPIO &pcfg_pull_up>;
               };
       };

       i2c_gpio18 {
               pinctrl_i2c_gpio18: i2c_gpio18-0 {
                       rockchip,pins =
                               <2 RK_PB2 RK_FUNC_GPIO &pcfg_pull_up>,
                               <2 RK_PB1 RK_FUNC_GPIO &pcfg_pull_up>;
               };
       };

       i2c_gpio19 {
               pinctrl_i2c_gpio19: i2c_gpio19-0 {
                       rockchip,pins =
                               <2 RK_PB4 RK_FUNC_GPIO &pcfg_pull_up>,
                               <2 RK_PB3 RK_FUNC_GPIO &pcfg_pull_up>;
               };
       };

       i2c_gpio20 {
               pinctrl_i2c_gpio20: i2c_gpio20-0 {
                       rockchip,pins =
                               <2 RK_PB6 RK_FUNC_GPIO &pcfg_pull_up>,
                               <2 RK_PB5 RK_FUNC_GPIO &pcfg_pull_up>;
               };
       };

       i2c_gpio21 {
               pinctrl_i2c_gpio21: i2c_gpio21-0 {
                       rockchip,pins =
                               <2 RK_PC0 RK_FUNC_GPIO &pcfg_pull_up>,
                               <2 RK_PB7 RK_FUNC_GPIO &pcfg_pull_up>;
               };
       };

       i2c_gpio22 {
               pinctrl_i2c_gpio22: i2c_gpio22-0 {
                       rockchip,pins =
                               <2 RK_PC2 RK_FUNC_GPIO &pcfg_pull_up>,
                               <2 RK_PC1 RK_FUNC_GPIO &pcfg_pull_up>;
               };
       };

       i2c_gpio23 {
               pinctrl_i2c_gpio23: i2c_gpio23-0 {
                       rockchip,pins =
                               <2 RK_PC4 RK_FUNC_GPIO &pcfg_pull_up>,
                               <2 RK_PC3 RK_FUNC_GPIO &pcfg_pull_up>;
               };
       };

       i2c_gpio24 {
               pinctrl_i2c_gpio24: i2c_gpio24-0 {
                       rockchip,pins =
                               <2 RK_PC6 RK_FUNC_GPIO &pcfg_pull_up>,
                               <2 RK_PC5 RK_FUNC_GPIO &pcfg_pull_up>;
               };
       };

       i2c_gpio25 {
               pinctrl_i2c_gpio25: i2c_gpio25-0 {
                       rockchip,pins =
                               <0 RK_PA4 RK_FUNC_GPIO &pcfg_pull_up>,
                               <0 RK_PA5 RK_FUNC_GPIO &pcfg_pull_up>;
               };
       };

       i2c_gpio26 {
               pinctrl_i2c_gpio26: i2c_gpio26-0 {
                       rockchip,pins =
                               <2 RK_PA1 RK_FUNC_GPIO &pcfg_pull_up>,
                               <2 RK_PA2 RK_FUNC_GPIO &pcfg_pull_up>;
               };
       };

       i2c_gpio27 {
               pinctrl_i2c_gpio27: i2c_gpio27-0 {
                       rockchip,pins =
                               <1 RK_PD7 RK_FUNC_GPIO &pcfg_pull_up>,
                               <2 RK_PA0 RK_FUNC_GPIO &pcfg_pull_up>;
               };
       };

       i2c_gpio28 {
               pinctrl_i2c_gpio28: i2c_gpio28-0 {
                       rockchip,pins =
                               <1 RK_PD5 RK_FUNC_GPIO &pcfg_pull_up>,
                               <1 RK_PD6 RK_FUNC_GPIO &pcfg_pull_up>;
               };
       };

       i2c_gpio29 {
               pinctrl_i2c_gpio29: i2c_gpio29-0 {
                       rockchip,pins =
                               <4 RK_PC0 RK_FUNC_GPIO &pcfg_pull_up>,
                               <4 RK_PC1 RK_FUNC_GPIO &pcfg_pull_up>;
               };
       };

       i2c_gpio30 {
               pinctrl_i2c_gpio30: i2c_gpio30-0 {
                       rockchip,pins =
                               <4 RK_PB6 RK_FUNC_GPIO &pcfg_pull_up>,
                               <4 RK_PB7 RK_FUNC_GPIO &pcfg_pull_up>;
               };
       };

       i2c_gpio31 {
               pinctrl_i2c_gpio31: i2c_gpio31-0 {
                       rockchip,pins =
                               <4 RK_PB4 RK_FUNC_GPIO &pcfg_pull_up>,
                               <4 RK_PB5 RK_FUNC_GPIO &pcfg_pull_up>;
               };
       };

       i2c_gpio32 {
               pinctrl_i2c_gpio32: i2c_gpio32-0 {
                       rockchip,pins =
                               <4 RK_PB2 RK_FUNC_GPIO &pcfg_pull_up>,
                               <4 RK_PB3 RK_FUNC_GPIO &pcfg_pull_up>;
               };
       };

       i2c_gpio33 {
               pinctrl_i2c_gpio33: i2c_gpio33-0 {
                       rockchip,pins =
                               <4 RK_PB0 RK_FUNC_GPIO &pcfg_pull_up>,
                               <4 RK_PB1 RK_FUNC_GPIO &pcfg_pull_up>;
               };
       };

       i2c_gpio34 {
               pinctrl_i2c_gpio34: i2c_gpio34-0 {
                       rockchip,pins =
                               <4 RK_PA6 RK_FUNC_GPIO &pcfg_pull_up>,
                               <4 RK_PA7 RK_FUNC_GPIO &pcfg_pull_up>;
               };
       };

       i2c_gpio35 {
               pinctrl_i2c_gpio35: i2c_gpio35-0 {
                       rockchip,pins =
                               <4 RK_PA4 RK_FUNC_GPIO &pcfg_pull_up>,
                               <4 RK_PA5 RK_FUNC_GPIO &pcfg_pull_up>;
               };
       };

       i2c_gpio36 {
               pinctrl_i2c_gpio36: i2c_gpio36-0 {
                       rockchip,pins =
                               <4 RK_PA2 RK_FUNC_GPIO &pcfg_pull_up>,
                               <4 RK_PA3 RK_FUNC_GPIO &pcfg_pull_up>;
               };
       };

       i2c_gpio37 {
               pinctrl_i2c_gpio37: i2c_gpio37-0 {
                       rockchip,pins =
                               <4 RK_PA0 RK_FUNC_GPIO &pcfg_pull_up>,
                               <4 RK_PA1 RK_FUNC_GPIO &pcfg_pull_up>;
               };
       };

       i2c_gpio38 {
               pinctrl_i2c_gpio38: i2c_gpio38-0 {
                       rockchip,pins =
                               <3 RK_PD6 RK_FUNC_GPIO &pcfg_pull_up>,
                               <3 RK_PD7 RK_FUNC_GPIO &pcfg_pull_up>;
               };
       };

       i2c_gpio39 {
               pinctrl_i2c_gpio39: i2c_gpio39-0 {
                       rockchip,pins =
                               <3 RK_PD4 RK_FUNC_GPIO &pcfg_pull_up>,
                               <3 RK_PD5 RK_FUNC_GPIO &pcfg_pull_up>;
               };
       };

       i2c_gpio40 {
               pinctrl_i2c_gpio40: i2c_gpio40-0 {
                       rockchip,pins =
                               <3 RK_PD2 RK_FUNC_GPIO &pcfg_pull_up>,
                               <3 RK_PD3 RK_FUNC_GPIO &pcfg_pull_up>;
               };
       };

       i2c_gpio41 {
               pinctrl_i2c_gpio41: i2c_gpio41-0 {
                       rockchip,pins =
                               <3 RK_PD0 RK_FUNC_GPIO &pcfg_pull_up>,
                               <3 RK_PD1 RK_FUNC_GPIO &pcfg_pull_up>;
               };
       };

       i2c_gpio42 {
               pinctrl_i2c_gpio42: i2c_gpio42-0 {
                       rockchip,pins =
                               <3 RK_PC6 RK_FUNC_GPIO &pcfg_pull_up>,
                               <3 RK_PC7 RK_FUNC_GPIO &pcfg_pull_up>;
               };
       };

       i2c_gpio43 {
               pinctrl_i2c_gpio43: i2c_gpio43-0 {
                       rockchip,pins =
                               <3 RK_PC4 RK_FUNC_GPIO &pcfg_pull_up>,
                               <3 RK_PC5 RK_FUNC_GPIO &pcfg_pull_up>;
               };
       };

       i2c_gpio44 {
               pinctrl_i2c_gpio44: i2c_gpio44-0 {
                       rockchip,pins =
                               <3 RK_PC2 RK_FUNC_GPIO &pcfg_pull_up>,
                               <3 RK_PC3 RK_FUNC_GPIO &pcfg_pull_up>;
               };
       };

       i2c_gpio45 {
               pinctrl_i2c_gpio45: i2c_gpio45-0 {
                       rockchip,pins =
                               <3 RK_PC0 RK_FUNC_GPIO &pcfg_pull_up>,
                               <3 RK_PC1 RK_FUNC_GPIO &pcfg_pull_up>;
               };
       };

       i2c_gpio46 {
               pinctrl_i2c_gpio46: i2c_gpio46-0 {
                       rockchip,pins =
                               <3 RK_PB6 RK_FUNC_GPIO &pcfg_pull_up>,
                               <3 RK_PB7 RK_FUNC_GPIO &pcfg_pull_up>;
               };
       };

       i2c_gpio47 {
               pinctrl_i2c_gpio47: i2c_gpio47-0 {
                       rockchip,pins =
                               <3 RK_PB4 RK_FUNC_GPIO &pcfg_pull_up>,
                               <3 RK_PB5 RK_FUNC_GPIO &pcfg_pull_up>;
               };
       };

       i2c_gpio48 {
               pinctrl_i2c_gpio48: i2c_gpio48-0 {
                       rockchip,pins =
                               <3 RK_PB2 RK_FUNC_GPIO &pcfg_pull_up>,
                               <3 RK_PB3 RK_FUNC_GPIO &pcfg_pull_up>;
               };
       };

       i2c_gpio49 {
               pinctrl_i2c_gpio49: i2c_gpio49-0 {
                       rockchip,pins =
                               <3 RK_PB0 RK_FUNC_GPIO &pcfg_pull_up>,
                               <3 RK_PB1 RK_FUNC_GPIO &pcfg_pull_up>;
               };
       };

       i2c_gpio50 {
               pinctrl_i2c_gpio50: i2c_gpio50-0 {
                       rockchip,pins =
                               <3 RK_PA6 RK_FUNC_GPIO &pcfg_pull_up>,
                               <3 RK_PA7 RK_FUNC_GPIO &pcfg_pull_up>;
               };
       };

       i2c_gpio51 {
               pinctrl_i2c_gpio51: i2c_gpio51-0 {
                       rockchip,pins =
                               <3 RK_PA4 RK_FUNC_GPIO &pcfg_pull_up>,
                               <3 RK_PA5 RK_FUNC_GPIO &pcfg_pull_up>;
               };
       };

       i2c_gpio52 {
               pinctrl_i2c_gpio52: i2c_gpio52-0 {
                       rockchip,pins =
                               <3 RK_PA2 RK_FUNC_GPIO &pcfg_pull_up>,
                               <3 RK_PA3 RK_FUNC_GPIO &pcfg_pull_up>;
               };
       };
};

&pmu_io_domains {
	pmuio1-supply = <&vcc3v3_pmu>;
	pmuio2-supply = <&vcc3v3_pmu>;
	vccio1-supply = <&vccio_acodec>;
	vccio2-supply = <&vcc_1v8>;
	vccio3-supply = <&vccio_sd>;
	vccio4-supply = <&vcc_1v8>;
	vccio5-supply = <&vcc_3v3>;
	vccio6-supply = <&vcc_1v8>;
	vccio7-supply = <&vcc_3v3>;
	status = "okay";
};

&saradc {
	vref-supply = <&vcca_1v8>;
	status = "okay";
};

&sdhci {
	bus-width = <8>;
	mmc-hs200-1_8v;
	non-removable;
	vmmc-supply = <&vcc_3v3>;
	vqmmc-supply = <&vcc_1v8>;
	status = "okay";
};


&tsadc {
	status = "okay";
};

&uart2 {
	status = "okay";
};

&usb_host0_xhci {
	dr_mode = "host";
	status = "okay";
};

&usb2phy0 {
	status = "okay";
};

&usb2phy0_host {
	status = "okay";
};

&usb2phy0_otg {
	status = "okay";
};

&usb_host1_xhci {
	status = "okay";
};

&usb2phy1 {
	status = "okay";
};

&usb2phy1_host {
	status = "okay";
};

&usb2phy1_otg {
	status = "okay";
};

&vop {
	assigned-clocks = <&cru DCLK_VOP0>, <&cru DCLK_VOP1>;
	assigned-clock-parents = <&pmucru PLL_HPLL>, <&cru PLL_VPLL>;
	status = "okay";
};

&vpu {
	status = "okay";
};

&vop_mmu {
	status = "okay";
};

